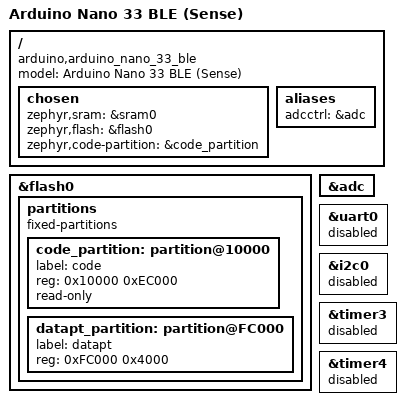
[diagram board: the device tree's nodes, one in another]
/ {
	model = "Arduino Nano 33 BLE (Sense)";
	compatible = "arduino,arduino_nano_33_ble";

	chosen {
		/delete-property/ zephyr,console;
		/delete-property/ zephyr,shell-uart;
		/delete-property/ zephyr,uart-mcumgr;
		/delete-property/ zephyr,bt-mon-uart;
		/delete-property/ zephyr,bt-c2h-uart;
		zephyr,sram = &sram0;
		zephyr,flash = &flash0;
		zephyr,code-partition = &code_partition;
	};

	aliases {
        adcctrl = &adc;
	};
};

/* Flash Layout
 *    Bootloader    0x00000 - 0x10000 (Size 0x10000 65536 Bytes)
 *    Code          0x10000 - 0xFC000 (Size 0xEC000 966656 Bytes)
 *    NVM Data      0xFC000 - 0x100000 (Size 0x4000 16384 Bytes)
 */

&flash0 {
	partitions {
		compatible = "fixed-partitions";
		#address-cells = <1>;
		#size-cells = <1>;

		code_partition: partition@10000 {
			label = "code";
			reg = <0x10000 0xEC000>;
			read-only;
		};

        datapt_partition: partition@FC000 {
            label = "datapt";
            reg = <0xFC000 0x4000>;
        };
	};
};

&adc {
	status = "okay";
};

&uart0 {
	status = "disabled";
};

&i2c0 {
	status = "disabled";
};

/* Disable Timer3, used by PPM output
 */
&timer3 {
    status = "disabled";
};

/* Disable Timer4, used by PPM input
 */
&timer4 {
    status = "disabled";
};

